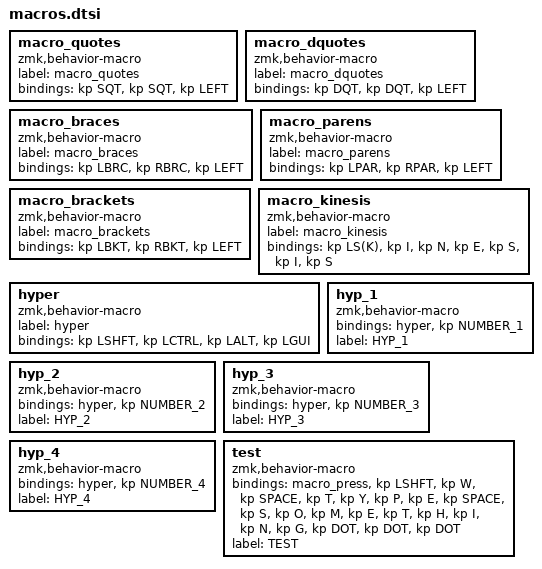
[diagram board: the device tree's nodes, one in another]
  macro_quotes: macro_quotes {
    compatible = "zmk,behavior-macro";
    label = "macro_quotes";
    #binding-cells = <0>;
    bindings = <&kp SQT>, <&kp SQT>, <&kp LEFT>;
  };
  macro_dquotes: macro_dquotes {
    compatible = "zmk,behavior-macro";
    label = "macro_dquotes";
    #binding-cells = <0>;
    bindings = <&kp DQT>, <&kp DQT>, <&kp LEFT>;
  };
  macro_braces: macro_braces {
    compatible = "zmk,behavior-macro";
    label = "macro_braces";
    #binding-cells = <0>;
    bindings = <&kp LBRC>, <&kp RBRC>, <&kp LEFT>;
  };
  macro_parens: macro_parens {
    compatible = "zmk,behavior-macro";
    label = "macro_parens";
    #binding-cells = <0>;
    bindings = <&kp LPAR>, <&kp RPAR>, <&kp LEFT>;
  };
  macro_brackets: macro_brackets {
    compatible = "zmk,behavior-macro";
    label = "macro_brackets";
    #binding-cells = <0>;
    bindings = <&kp LBKT>, <&kp RBKT>, <&kp LEFT>;
  };
  macro_kinesis: macro_kinesis {
    compatible = "zmk,behavior-macro";
    label = "macro_kinesis";
    #binding-cells = <0>;
    bindings = <&kp LS(K)>, <&kp I>, <&kp N>, <&kp E>, <&kp S>, <&kp I>, <&kp S>;
  };
  hyper: hyper {
    compatible = "zmk,behavior-macro";
    label = "hyper";
    #binding-cells = <0>;
    bindings = <&kp LSHFT &kp LCTRL &kp LALT &kp LGUI>;
  };

  hyp_1: hyp_1 {
    compatible = "zmk,behavior-macro";
    #binding-cells = <0>;
    bindings = <&hyper &kp NUMBER_1>;
    label = "HYP_1";
  };

  hyp_2: hyp_2 {
    compatible = "zmk,behavior-macro";
    #binding-cells = <0>;
    bindings = <&hyper &kp NUMBER_2>;
    label = "HYP_2";
  };

  hyp_3: hyp_3 {
    compatible = "zmk,behavior-macro";
    #binding-cells = <0>;
    bindings = <&hyper &kp NUMBER_3>;
    label = "HYP_3";
  };

  hyp_4: hyp_4 {
    compatible = "zmk,behavior-macro";
    #binding-cells = <0>;
    bindings = <&hyper &kp NUMBER_4>;
    label = "HYP_4";
  };

  test: test {
    compatible = "zmk,behavior-macro";
    #binding-cells = <0>;
    bindings =
        <&macro_press>,
        <&kp LSHFT &kp W &kp SPACE &kp T &kp Y &kp P &kp E &kp SPACE &kp S &kp O &kp M &kp E &kp T &kp H &kp I &kp N &kp G &kp DOT &kp DOT &kp DOT>;

    label = "TEST";
  };
